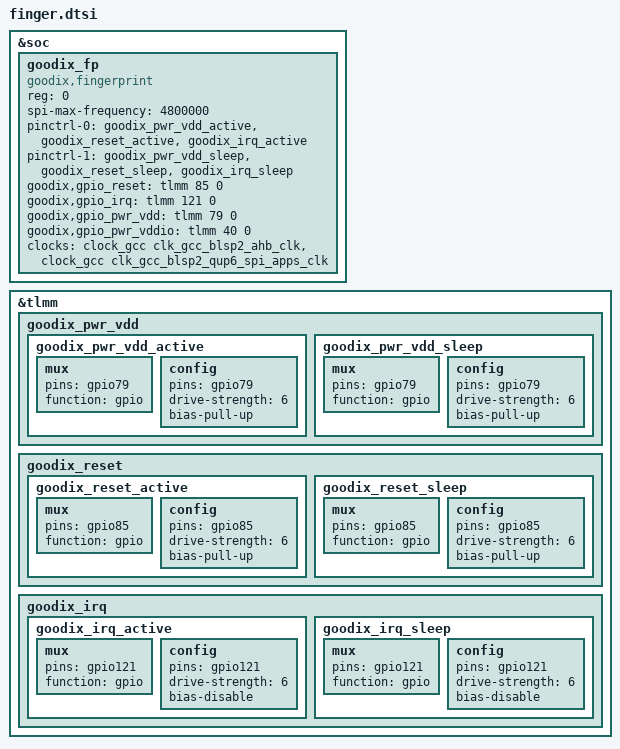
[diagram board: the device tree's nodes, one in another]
/*
 * nubia NX609J finger dts
 */
&soc {
	// add goodix fingerprint as platform device
	goodix_fp{
	        status = "ok";
	        reg = <0>;
	        compatible = "goodix,fingerprint";
	        spi-max-frequency = <4800000>;
	        pinctrl-names = "gf_fp_active", "gf_fp_suspend";
	        pinctrl-0 = <&goodix_pwr_vdd_active &goodix_reset_active &goodix_irq_active>;
	        pinctrl-1 = <&goodix_pwr_vdd_sleep &goodix_reset_sleep &goodix_irq_sleep>;
	        goodix,gpio_reset = <&tlmm 85 0>;
	        goodix,gpio_irq = <&tlmm 121 0>;
	        goodix,gpio_pwr_vdd = <&tlmm 79 0>;
	        goodix,gpio_pwr_vddio = <&tlmm 40 0>;
	        clock-names = "iface_clk", "core_clk";
	        clocks = <&clock_gcc clk_gcc_blsp2_ahb_clk>,<&clock_gcc clk_gcc_blsp2_qup6_spi_apps_clk>;
	};

	/delete-node/ qcom,qbt1000;
};

&tlmm {
		goodix_pwr_vdd {
			goodix_pwr_vdd_active: goodix_pwr_vdd_active {
				mux {
					pins = "gpio79";
					function = "gpio";
				};

				config {
					pins = "gpio79";
					drive-strength = <6>;
					bias-pull-up;
				};
			};

			goodix_pwr_vdd_sleep: goodix_pwr_vdd_sleep {
				mux {
					pins = "gpio79";
					function = "gpio";
				};

				config {
					pins = "gpio79";
					drive-strength = <6>;
					bias-pull-up;
				};
			};
		};
		goodix_reset {
			goodix_reset_active: goodix_reset_active {
				mux {
					pins = "gpio85";
					function = "gpio";
				};

				config {
					pins = "gpio85";
					drive-strength = <6>;
					bias-pull-up;
				};
			};

			goodix_reset_sleep: goodix_reset_sleep {
				mux {
					pins = "gpio85";
					function = "gpio";
				};

				config {
					pins = "gpio85";
					drive-strength = <6>;
					bias-pull-up;
				};
			};
		};

		goodix_irq {
			goodix_irq_active: goodix_irq_active {
				mux {
					pins = "gpio121";
					function = "gpio";
				};

				config {
					pins = "gpio121";
					drive-strength = <6>;
					bias-disable;
				};
			};

			goodix_irq_sleep: goodix_irq_sleep {
				mux {
					pins = "gpio121";
					function = "gpio";
				};

				config {
					pins = "gpio121";
					drive-strength = <6>;
					bias-disable;
				};
			};
		};
};


